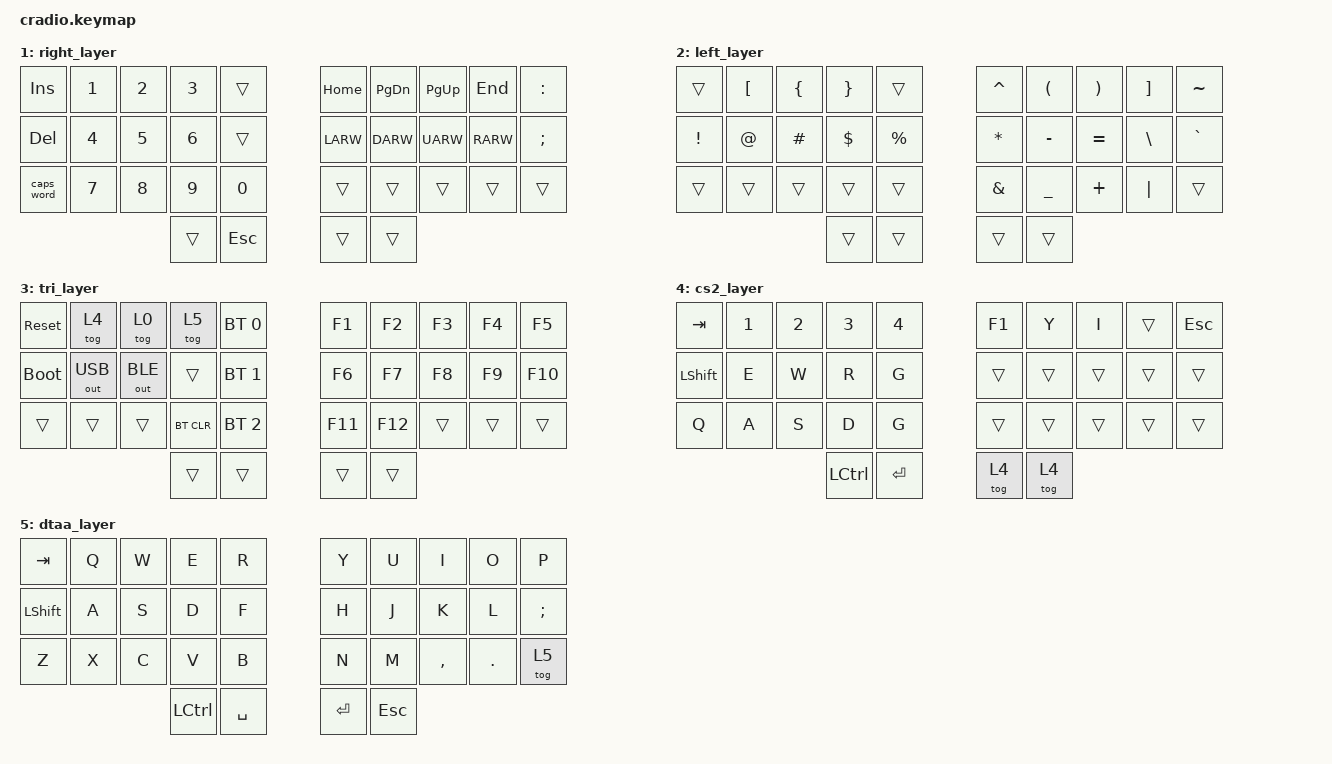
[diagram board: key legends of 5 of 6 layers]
// Copyright (c) 2022 The ZMK Contributors
// SPDX-License-Identifier: MIT

#include <behaviors.dtsi>
#include <dt-bindings/zmk/keys.h>
#include <dt-bindings/zmk/bt.h>
#include <dt-bindings/zmk/outputs.h>

// Home row mods macro
#define HRML(k1,k2,k3,k4) &ht LSHFT k1  &ht LALT k2  &ht LCTRL k3  &ht LGUI k4
#define HRMR(k1,k2,k3,k4) &ht RGUI k1  &ht RCTRL k2  &ht RALT k3  &ht RSHFT k4

/ {
    behaviors {
        ht: hold_tap {
            compatible = "zmk,behavior-hold-tap";
            #binding-cells = <2>;
            flavor = "tap-preferred";
            tapping-term-ms = <220>;
            quick-tap-ms = <150>;
            require-prior-idle-ms = <100>;
            bindings = <&kp>, <&kp>;
        };
    };

    conditional_layers {
        compatible = "zmk,conditional-layers";
        tri_layer {
            if-layers = <1 2>;
            then-layer = <3>;
        };
    };

    keymap {
        compatible = "zmk,keymap";
        default_layer {
            bindings = <
        //╭──────────┬──────────┬──────────┬──────────┬──────────╮   ╭──────────┬──────────┬──────────┬──────────┬──────────╮
        //│  Q       │  W       │  E       │  R       │  T       │   │  Y       │  U       │  I       │  O       │  P       │
            &kp Q      &kp W      &kp E      &kp R      &kp T          &kp Y      &kp U      &kp I      &kp O      &kp P
        //├──────────┼──────────┼──────────┼──────────┼──────────┤   ├──────────┼──────────┼──────────┼──────────┼──────────┤
        //│  A       │  S       │  D       │  F       │  G       │   │  H       │  J       │  K       │  L       │ ' "      │
            HRML(A,        S,         D,         F)     &kp G          &kp H      HRMR(J,        K,         L,        SQT)
        //├──────────┼──────────┼──────────┼──────────┼──────────┤   ├──────────┼──────────┼──────────┼──────────┼──────────┤
        //│  Z       │  X       │  C       │  V       │  B       │   │  N       │  M       │ , <      │ . >      │ / ?      │
            &kp Z      &kp X      &kp C      &kp V      &kp B          &kp N      &kp M      &kp COMMA  &kp DOT    &kp FSLH
        //╰──────────┴──────────┴──────────┼──────────┼──────────┤   ├──────────┼──────────┼──────────┴──────────┴──────────╯
                                            &lt 2 TAB   &kp ENTER     &kp SPACE  &lt 1 BSPC
        //                                 ╰──────────┴──────────╯   ╰──────────┴──────────╯
            >;
        };

        right_layer {
            bindings = <
        //╭──────────┬──────────┬──────────┬──────────┬──────────╮   ╭──────────┬──────────┬──────────┬──────────┬──────────╮
        //│ INSERT   │  1       │  2       │  3       │          │   │ HOME     │ PAGE DN  │ PAGE UP  │ END      │  :       │
            &kp INS    &kp N1     &kp N2     &kp N3     &trans         &kp HOME   &kp PG_DN  &kp PG_UP  &kp END    &kp COLON
        //├──────────┼──────────┼──────────┼──────────┼──────────┤   ├──────────┼──────────┼──────────┼──────────┼──────────┤
        //│ DELETE   │  4       │  5       │  6       │          │   │ LEFT     │ DOWN     │ UP       │ RIGHT    │  ;       │
            &kp DEL    &kp N4     &kp N5     &kp N6     &trans         &kp LARW   &kp DARW   &kp UARW   &kp RARW   &kp SEMI
        //├──────────┼──────────┼──────────┼──────────┼──────────┤   ├──────────┼──────────┼──────────┼──────────┼──────────┤
        //│ CAPS     │  7       │  8       │  9       │  0       │   │          │          │          │          │          │
           &caps_word  &kp N7     &kp N8     &kp N9     &kp N0         &trans     &trans     &trans     &trans     &trans
        //╰──────────┴──────────┴──────────┼──────────┼──────────┤   ├──────────┼──────────┼──────────┴──────────┴──────────╯
                                             &trans     &kp ESC        &trans     &trans
        //                                 ╰──────────┴──────────╯   ╰──────────┴──────────╯
            >;
        };

        left_layer {
            bindings = <
        //╭──────────┬──────────┬──────────┬──────────┬──────────╮   ╭──────────┬──────────┬──────────┬──────────┬──────────╮
        //│          │  [       │  {       │  }       │          │   │  ^       │  (       │  )       │  ]       │  ~       │
            &trans     &kp LBKT   &kp LBRC   &kp RBRC   &trans         &kp CARET  &kp LPAR   &kp RPAR   &kp RBKT   &kp TILDE
        //├──────────┼──────────┼──────────┼──────────┼──────────┤   ├──────────┼──────────┼──────────┼──────────┼──────────┤
        //│  !       │  @       │  #       │  $       │  %       │   │  *       │  -       │  =       │  \       │  `       │
            &kp EXCL   &kp AT     &kp HASH   &kp DLLR   &kp PRCNT      &kp ASTRK  &kp MINUS  &kp EQUAL  &kp BSLH   &kp GRAVE
        //├──────────┼──────────┼──────────┼──────────┼──────────┤   ├──────────┼──────────┼──────────┼──────────┼──────────┤
        //│          │          │          │          │          │   │  &       │  _       │  +       │  │       │          │
            &trans     &trans     &trans     &trans     &trans         &kp AMPS   &kp UNDER  &kp PLUS   &kp PIPE   &trans
        //╰──────────┴──────────┴──────────┼──────────┼──────────┤   ├──────────┼──────────┼──────────┴──────────┴──────────╯
                                             &trans     &trans         &trans     &trans
        //                                 ╰──────────┴──────────╯   ╰──────────┴──────────╯
            >;
        };

        tri_layer {
            bindings = <
        //╭──────────┬──────────┬──────────┬──────────┬──────────╮   ╭──────────┬──────────┬──────────┬──────────┬──────────╮
        //│ RESET    │  CS2     │  DEFAULT │   DTAA   │PROFILE 0 │   │    F1    │    F2    │    F3    │    F4    │    F5    │
           &sys_reset  &tog 4     &tog 0        &tog 5   &bt BT_SEL 0    &kp F1     &kp F2     &kp F3     &kp F4     &kp F5    
        //├──────────┼──────────┼──────────┼──────────┼──────────┤   ├──────────┼──────────┼──────────┼──────────┼──────────┤
        //│BOOTLOADER│  OUT_USB │ OUT_BLE  │          │PROFILE 1 │   │    F6    │    F7    │    F8    │    F9    │   F10    │
          &bootloader &out OUT_USB &out OUT_BLE &trans &bt BT_SEL 1    &kp F6     &kp F7     &kp F8     &kp F9     &kp F10    
        //├──────────┼──────────┼──────────┼──────────┼──────────┤   ├──────────┼──────────┼──────────┼──────────┼──────────┤
        //│          │          │          │ CLEAR BT │PROFILE 2 │   │   F11    │   F12    │          │          │          │
            &trans     &trans     &trans    &bt BT_CLR &bt BT_SEL 2    &kp F11    &kp F12    &trans     &trans     &trans    
        //╰──────────┴──────────┴──────────┼──────────┼──────────┤   ├──────────┼──────────┴──────────┴──────────┴──────────╯
                                             &trans     &trans         &trans     &trans
        //                                 ╰──────────┴──────────╯   ╰──────────┴──────────╯
            >;
        };

        cs2_layer {
            bindings = <
        //╭──────────┬──────────┬──────────┬──────────┬──────────╮   ╭──────────┬──────────┬──────────┬──────────┬──────────╮
        //│  TAB     │    1     │    2     │    3     │    4     │   │     F1   │     Y    │    I     │          │  ESC     │
           &kp TAB      &kp N1     &kp N2     &kp N3     &kp N4          &kp F1     &kp Y     &kp I      &trans      &kp ESC
        //├──────────┼──────────┼──────────┼──────────┼──────────┤   ├──────────┼──────────┼──────────┼──────────┼──────────┤
        //│  SHIFT   │    E     │    W     │     R    │    G     │   │          │          │          │          │          │
           &kp LSHIFT    &kp E     &kp W     &kp R      &kp G          &trans     &trans     &trans     &trans    &trans
        //├──────────┼──────────┼──────────┼──────────┼──────────┤   ├──────────┼──────────┼──────────┼──────────┼──────────┤
        //│    Q     │    A     │    S     │    D     │    G     │   │          │          │          │          │          │
            &kp Q       &kp A     &kp S       &kp D     &kp G           &trans     &trans     &trans     &trans     &trans
        //╰──────────┴──────────┴──────────┼──────────┼──────────┤   ├──────────┼──────────┼──────────┴──────────┴──────────╯
                                            &kp LCTRL  &kp ENTER       &tog 4     &tog 4
        //                                 ╰──────────┴──────────╯   ╰──────────┴──────────╯
            >;
        };

        dtaa_layer {
            bindings = <
        //╭──────────┬──────────┬──────────┬──────────┬──────────╮   ╭──────────┬──────────┬──────────┬──────────┬──────────╮
        //│  TAB     │    Q     │    W     │    E     │    R     │   │    Y     │    U     │    I     │    O     │    P     │
           &kp TAB      &kp Q     &kp W     &kp E     &kp R          &kp Y      &kp U      &kp I      &kp O      &kp P
        //├──────────┼──────────┼──────────┼──────────┼──────────┤   ├──────────┼──────────┼──────────┼──────────┼──────────┤
        //│  SHIFT   │    A     │    S     │    D     │    F     │   │    H     │    J     │    K     │    L     │    ;     │
           &kp LSHIFT    &kp A     &kp S     &kp D     &kp F          &kp H      &kp J      &kp K      &kp L      &kp SEMI
        //├──────────┼──────────┼──────────┼──────────┼──────────┤   ├──────────┼──────────┼──────────┼──────────┼──────────┤
        //│    Z     │    X     │    C     │    V     │    B     │   │    N     │    M     │    ,     │    .     │          │
            &kp Z       &kp X     &kp C     &kp V     &kp B          &kp N      &kp M      &kp COMMA  &kp DOT       &tog 5
        //╰──────────┴──────────┴──────────┼──────────┼──────────┤   ├──────────┼──────────┼──────────┴──────────┴──────────╯
                                            &kp LCTRL  &kp SPACE       &kp ENTER  &kp ESC
        //                                 ╰──────────┴──────────╯   ╰──────────┴──────────╯
            >;
        };
    };
};
